# RS1xxxx register map
Vendor: Silicon Lab Inc.; Series: ARMCM4; File version: 1.2
CPU: CM4 r1p0, little endian, MPU, FPU, 6 interrupt priority bits
Registers are 32-bit, read-write, reset 0x0 unless marked. A register's access mark holds for its fields unless they carry their own. Offsets are from the block's base; [hi:lo] are bit positions.

## HSPI — The SPI Interface is a full duplex serial host interface, which supports 8-bit and 32-bit data granularity. It also supports gated mode of SPI clock and both the low and the high frequency modes
Base 0x20200000
0x00 SPI_HOST_INTR 8-bit — SPI Host interupt resgister.
  [7:0] SPI_HOST_INTR — These bits indicate the interrupt vector value coming from system side.
0x02 SPI_RFIFO_START 8-bit reset 0x10 — SPI FIFO start Level Register.
  [7:0] SPI_RFIFO_ST — These bits indicate the interrupt vector value coming from system side.
0x04 SPI_RFIFO_AFULL_LEV 8-bit reset 0x8 — SPI RFIFO AFULL Level Register.
  [7:0] SPI_RFIFO_AFULL_LEV — These bits are used to program the FIFO occupancy level to trigger the Almost Full indication.
0x06 SPI_RFIFO_AEMPTY_LEV 8-bit reset 0x8 — SPI WFIFO Almost Empty Register.
  [7:0] SPI_RFIFO_AEMPTY_LEV — These bits are used to program the occupancy level to trigger the Almost Empty indication.
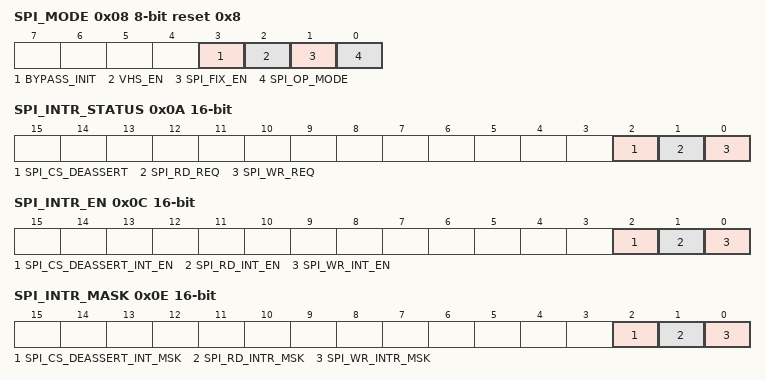
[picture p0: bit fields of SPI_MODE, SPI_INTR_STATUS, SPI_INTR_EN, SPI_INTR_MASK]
0x08 SPI_MODE 8-bit reset 0x8
  [3] BYPASS_INIT — This bit is used to bypass the SPI initialization.0 - Doesn't bypass,1 - bypasses SPI initialization
  [2] VHS_EN — This bit is used to enable Very high speed mode (120Mhz).
  [1] SPI_FIX_EN — This bit is used to enable the fix made for bus_ctrl_busy being asserted when success_state is being asserted getting deasserted when FSM has decided to move to BUSY_STATE or not.
  [0] SPI_OP_MODE — This bit is used to program the mode of working of SPI Interface.
0x0A SPI_INTR_STATUS 16-bit — SPI interrupt status register.
  [2] SPI_CS_DEASSERT — SPI chip deassert interrupt.
  [1] SPI_RD_REQ — Read request received.
  [0] SPI_WR_REQ — Write request received.
0x0C SPI_INTR_EN 16-bit — SPI interrupt enable register.
  [2] SPI_CS_DEASSERT_INT_EN — This bit is used to enable the interrupt due to wrong deassertion of CS.
  [1] SPI_RD_INT_EN — This bit is used to enable the read interrupt.
  [0] SPI_WR_INT_EN — This bit is used to enable the write interrupt.
0x0E SPI_INTR_MASK 16-bit — SPI interrupt Mask register
  [2] SPI_CS_DEASSERT_INT_MSK — This bit is used to mask the CS deassertion interrupt.
  [1] SPI_RD_INTR_MSK — This bit is used to mask the read interrupt.
  [0] SPI_WR_INTR_MSK — This bit is used to mask the write interrupt.
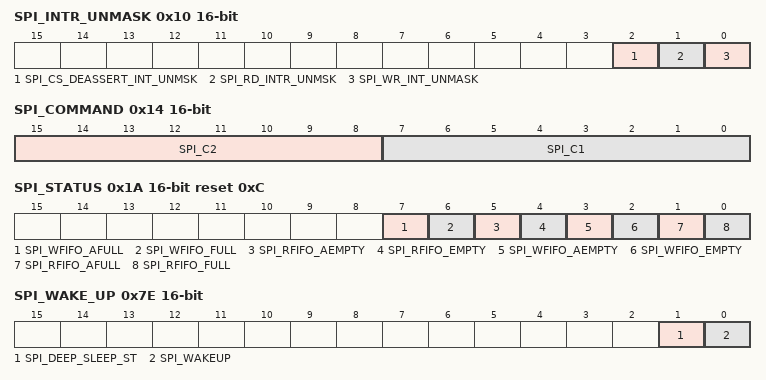
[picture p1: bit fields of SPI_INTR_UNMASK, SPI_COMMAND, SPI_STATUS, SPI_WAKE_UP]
0x10 SPI_INTR_UNMASK 16-bit — SPI interrupt unmask register
  [2] SPI_CS_DEASSERT_INT_UNMSK — This bit is used to unmask the CS deassertion interrupt.
  [1] SPI_RD_INTR_UNMSK — This bit is used to unmask the read interrupt.
  [0] SPI_WR_INT_UNMASK — This bit is used to unmask the write interrupt.
0x12 SPI_LENGTH 16-bit ro
  [15:0] SPI_LEN — These bit indicate the length of the transfer as transmitted in the Commands C3 and C4.
0x14 SPI_COMMAND 16-bit ro
  [15:8] SPI_C2 — These bits store the received command C2.
  [7:0] SPI_C1 — These bits store the received command C1.
0x16 SPI_DEV_ID 16-bit ro — SPI Device ID Register
  [15:0] SPI_DEVID — These bits store the Device ID information.
0x18 SPI_VERSION 16-bit ro — SPI Device ID Register
  [7:0] SPI_VERNO — These bits store the version number.
0x1A SPI_STATUS 16-bit ro reset 0xC
  [7] SPI_WFIFO_AFULL — This bit indicates if write FIFO is full (Write from Host to SOC).
  [6] SPI_WFIFO_FULL — This bit indicates if write FIFO is full (Write from Host to SOC).
  [5] SPI_RFIFO_AEMPTY — This bit indicates if read FIFO is empty (Read from SOC to host).
  [4] SPI_RFIFO_EMPTY — This bit indicates if read FIFO is empty (Read from SOC to host).
  [3] SPI_WFIFO_AEMPTY — This bit indicates if write FIFO is almost empty.
  [2] SPI_WFIFO_EMPTY — This bit indicates if write FIFO is empty.
  [1] SPI_RFIFO_AFULL — This bit indicates if the read FIFO is almost full.
  [0] SPI_RFIFO_FULL — This bit indicates if the read FIFO is almost full.
0x1C SPI_BC_STATE 16-bit ro — SPI Bus Controller State Register
  [13:0] SPI_BC — These bits indicate the Bus Controller FSM state.
0x7C SPI_SYS_RESET_REQ 16-bit
  [0] SPI_SYS_RESET_REQ — When set generates system reset request to reset controller. This gets reset once, reset controller generates reset. Host should not reset this bit. With this reset request, reset controller generates non por reset.
0x7E SPI_WAKE_UP 16-bit
  [1] SPI_DEEP_SLEEP_ST — Deep Sleep Start,Indicates the device to enter Deep Sleep state for maximum power save.
  [0] SPI_WAKEUP — Wakeup Interrupt,Interrupt for waking up the system from Deep Sleep.
0x380 SPI_RFIFO_DATA ro
  [31:0] SPI_RFIFO — These bits store the data received from the host
0x3C0 SPI_WFIFO_DATA wo
  [31:0] SPI_WFIFO — These bits are used to write, the data to be sent to the host.
